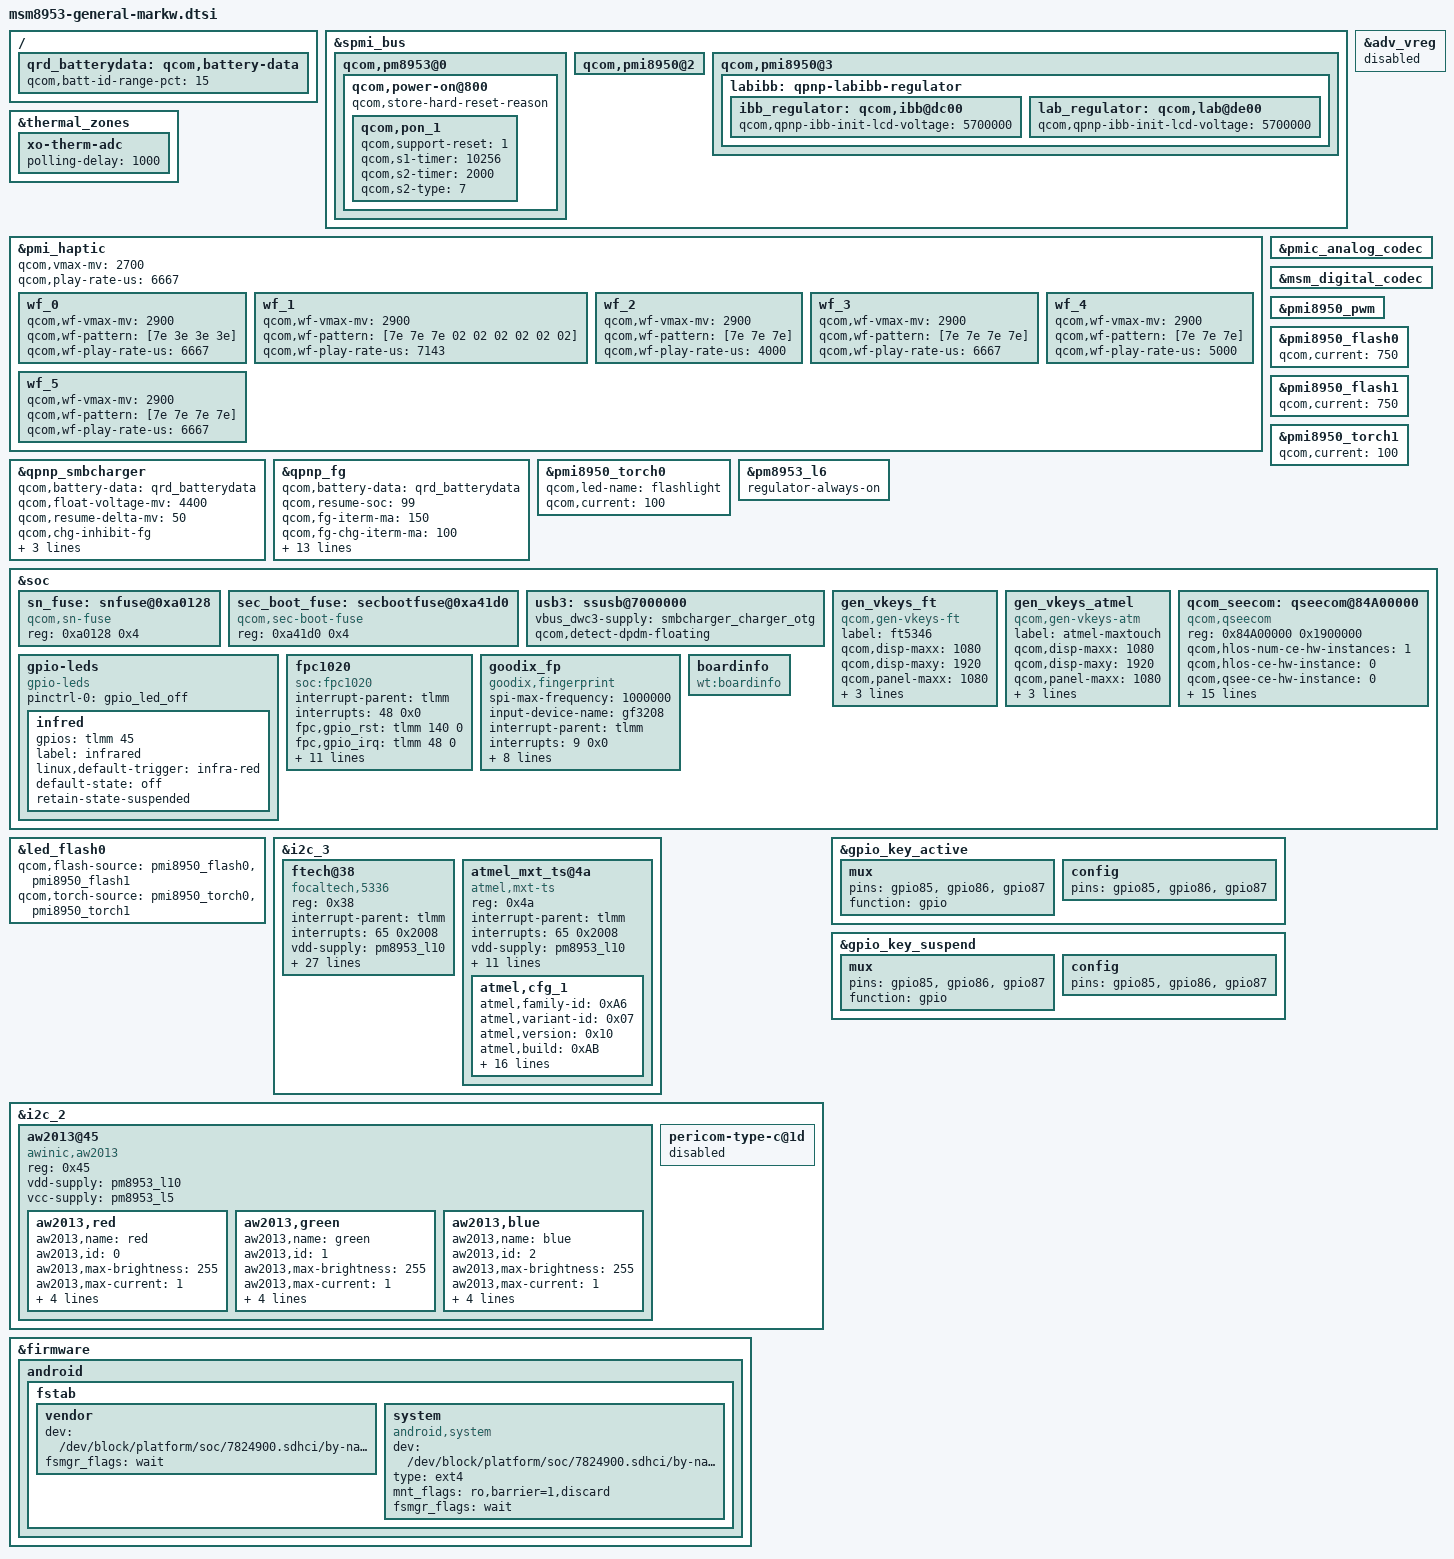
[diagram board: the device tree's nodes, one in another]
/* Copyright (c) 2017, The Linux Foundation. All rights reserved.
 *
 * This program is free software; you can redistribute it and/or modify
 * it under the terms of the GNU General Public License version 2 and
 * only version 2 as published by the Free Software Foundation.
 *
 * This program is distributed in the hope that it will be useful,
 * but WITHOUT ANY WARRANTY; without even the implied warranty of
 * MERCHANTABILITY or FITNESS FOR A PARTICULAR PURPOSE.  See the
 * GNU General Public License for more details.
 */

&spmi_bus {
	qcom,pm8953@0 {
		qcom,power-on@800 {
			qcom,store-hard-reset-reason;
			qcom,pon_1 {
				qcom,support-reset = <1>;
				qcom,s1-timer = <10256>;
				qcom,s2-timer = <2000>;
				qcom,s2-type = <7>;
		       };
		};
		/delete-node/ qcom,pm8953_typec@bf00;
          };

	qcom,pmi8950@2 {
        /delete-node/ qcom,leds@a100;
        };
    qcom,pmi8950@3 {
		labibb: qpnp-labibb-regulator {
			ibb_regulator: qcom,ibb@dc00 {
				/delete-property/
					qcom,qpnp-ibb-use-default-voltage;
				qcom,qpnp-ibb-init-lcd-voltage = <5700000>;
			};

			lab_regulator: qcom,lab@de00 {
				/delete-property/
					qcom,qpnp-ibb-use-default-voltage;
				qcom,qpnp-ibb-init-lcd-voltage = <5700000>;
			};
		};
	};
};

&adv_vreg {
	status = "disabled";
};

&thermal_zones {
	/delete-node/ pa-therm1-adc;
};

&pmi_haptic {
	status = "okay";
	qcom,vmax-mv = <2700>;
	qcom,play-rate-us = <6667>;
	wf_0 {
		qcom,wf-vmax-mv = <2900>;
		qcom,wf-pattern = [7e 3e 3e 3e];
		qcom,wf-play-rate-us = <6667>;
	};
	wf_1 {
		qcom,wf-vmax-mv = <2900>;
		qcom,wf-pattern = [7e 7e 7e 02 02 02 02 02 02];
		qcom,wf-play-rate-us = <7143>;
	};
	wf_2 {
		qcom,wf-vmax-mv = <2900>;
		qcom,wf-pattern = [7e 7e 7e];
		qcom,wf-play-rate-us = <4000>;
	};
	wf_3 {
		qcom,wf-vmax-mv = <2900>;
		qcom,wf-pattern = [7e 7e 7e 7e];
		qcom,wf-play-rate-us = <6667>;
	};
	wf_4 {
		qcom,wf-vmax-mv = <2900>;
		qcom,wf-pattern = [7e 7e 7e];
		qcom,wf-play-rate-us = <5000>;
	};
	wf_5 {
		qcom,wf-vmax-mv = <2900>;
		qcom,wf-pattern = [7e 7e 7e 7e];
		qcom,wf-play-rate-us = <6667>;
	};
};

&pmic_analog_codec {
	status = "okay";
};

&msm_digital_codec {
	status = "okay";
};

&qpnp_smbcharger {
	qcom,battery-data = <&qrd_batterydata>;
	qcom,float-voltage-mv = <4400>;
	qcom,resume-delta-mv = <50>;
        qcom,chg-inhibit-fg;
	qcom,thermal-mitigation = <2000 1200 1000 800 800>;
	qcom,charge-unknown-battery;
	/delete-property/ qcom,parallel-usb-min-current-ma;
	/delete-property/ qcom,parallel-usb-9v-min-current-ma;
	/delete-property/ qcom,parallel-allowed-lowering-ma;
	/delete-property/ qcom,chg-led-sw-controls;
	/delete-property/ qcom,chg-led-support;
	/delete-property/ qcom,external-typec;
	/delete-property/ qcom,typec-psy-name;
};

&qpnp_fg {
        qcom,battery-data = <&qrd_batterydata>;
	qcom,resume-soc = <99>;
	qcom,fg-iterm-ma = <150>;
	qcom,fg-chg-iterm-ma = <100>;
	qcom,fg-cutoff-voltage-mv = <3400>;
	qcom,fg-cc-cv-threshold-mv = <4390>;
	qcom,fg-vbat-estimate-diff-mv = <3200>;
	qcom,cold-bat-decidegc = <(0)>;
	qcom,cool-bat-decidegc = <(100)>;
	qcom,hot-bat-decidegc = <600>;
	qcom,warm-bat-decidegc = <450>;
	qcom,cl-max-increment-deciperc = <1>;
	qcom,cl-max-decrement-deciperc = <1>;
	qcom,fg-delta-soc = <1>;
        qcom,bad-battery-detection-enable;
	qcom,hold-soc-while-full;
	qcom,thermal-coefficients = [c2 86 bb 50 cf 37];
};

&pmi8950_pwm {
    status = "okay";
};
		
&pmi8950_flash0 {
	qcom,current = <750>;
};

&pmi8950_flash1 {
	qcom,current = <750>;
};

&pmi8950_torch1 {
	qcom,current = <100>;
};

&pmi8950_torch0 {
    qcom,led-name = "flashlight";
	qcom,current = <100>;
};

&pm8953_l6 {
	regulator-always-on;
};

&soc {
	sn_fuse: snfuse@0xa0128 {
		compatible = "qcom,sn-fuse";
		reg = <0xa0128 0x4>;
		reg-names = "sn-base";
	};

	sec_boot_fuse: secbootfuse@0xa41d0 {
		compatible = "qcom,sec-boot-fuse";
		reg = <0xa41d0 0x4>;
		reg-names = "sec-boot-base";
	};

	usb3: ssusb@7000000 {
		vbus_dwc3-supply = <&smbcharger_charger_otg>;
		qcom,detect-dpdm-floating;
	};

	gen_vkeys_ft {
		compatible = "qcom,gen-vkeys-ft";
		label = "ft5346";
		qcom,disp-maxx = <1080>;
		qcom,disp-maxy = <1920>;
		qcom,panel-maxx = <1080>;
		qcom,panel-maxy = <2080>;
		qcom,key-codes = <139 172 158>;
		qcom,y-offset = <0>;
	};
	gen_vkeys_atmel {
		compatible = "qcom,gen-vkeys-atm";
		label = "atmel-maxtouch";
		qcom,disp-maxx = <1080>;
		qcom,disp-maxy = <1920>;
		qcom,panel-maxx = <1080>;
		qcom,panel-maxy = <2080>;
		qcom,key-codes = <139 172 158>;
		qcom,y-offset = <0>;
	};

	qcom_seecom: qseecom@84A00000 {
		compatible = "qcom,qseecom";
		reg = <0x84A00000 0x1900000>;
		reg-names = "secapp-region";
		qcom,hlos-num-ce-hw-instances = <1>;
		qcom,hlos-ce-hw-instance = <0>;
		qcom,qsee-ce-hw-instance = <0>;
		qcom,disk-encrypt-pipe-pair = <2>;
		qcom,support-fde;
		qcom,msm-bus,name = "qseecom-noc";
		qcom,msm-bus,num-cases = <4>;
		qcom,msm-bus,num-paths = <1>;
		qcom,support-bus-scaling;
		qcom,appsbl-qseecom-support;
		qcom,msm-bus,vectors-KBps =
			<55 512 0 0>,
			<55 512 0 0>,
			<55 512 120000 1200000>,
			<55 512 393600 3936000>;
		clocks = <&clock_gcc clk_crypto_clk_src>,
			 <&clock_gcc clk_gcc_crypto_clk>,
			 <&clock_gcc clk_gcc_crypto_ahb_clk>,
			 <&clock_gcc clk_gcc_crypto_axi_clk>;
		clock-names = "core_clk_src", "core_clk",
				"iface_clk", "bus_clk";
		qcom,ce-opp-freq = <100000000>;
	};

	/delete-node/ qseecom@85b00000;

	gpio-leds {
		compatible = "gpio-leds";
		status = "okay";
		pinctrl-names = "default";
		pinctrl-0 = <&gpio_led_off>;

			infred {
			gpios = <&tlmm 45 0>;
			label = "infrared";
			linux,default-trigger = "infra-red";
			default-state = "off";
			retain-state-suspended;
		};
	};

	fpc1020 {
		compatible = "soc:fpc1020";

		interrupt-parent = <&tlmm>;
		interrupts = <48 0x0>;

		fpc,gpio_rst    = <&tlmm 140 0>;
		fpc,gpio_irq    = <&tlmm 48 0>;

		vcc_spi-supply  = <&pm8953_l5>;
		vdd_ana-supply  = <&pm8953_l5>;
		vdd_io-supply   = <&pm8953_l5>;

		fpc,enable-on-boot;
		/delete-property/
		fpc,enable-wakeup;

		fpc,spi-max-frequency = <4800000>;

		/*For SPI Clock Handled by Linux*/
		clock-names = "iface_clk", "core_clk";
		clocks = <&clock_gcc clk_gcc_blsp1_ahb_clk>,
		<&clock_gcc clk_gcc_blsp1_qup1_spi_apps_clk>;

		pinctrl-names = "fpc1020_spi_active",
			"fpc1020_reset_reset",
			"fpc1020_reset_active",
			"fpc1020_irq_active";

		pinctrl-0 = <&fpc_spi_active>;
		pinctrl-1 = <&fpc_reset_reset>;
		pinctrl-2 = <&fpc_reset_active>;
		pinctrl-3 = <&fpc_irq_active>;
	};

	goodix_fp {
		compatible = "goodix,fingerprint";
		spi-max-frequency = <1000000>;
		input-device-name = "gf3208";
		interrupt-parent = <&tlmm>;
		interrupts = <9 0x0>;

		goodix,gpio_reset    = <&tlmm 140 0>;
		goodix,gpio_irq      = <&tlmm 48 0>;

		clock-names = "iface_clk", "core_clk";
		clocks = <&clock_gcc clk_gcc_blsp1_ahb_clk>,
		<&clock_gcc clk_gcc_blsp1_qup1_spi_apps_clk>;

		pinctrl-names = "goodixfp_spi_active",
				"goodixfp_reset_reset",
				"goodixfp_reset_active",
				"goodixfp_irq_active";

		pinctrl-0 = <&goodix_spi_active>;
		pinctrl-1 = <&goodix_reset_reset>;
		pinctrl-2 = <&goodix_reset_active>;
		pinctrl-3 = <&goodix_irq_active>;
    };

	boardinfo {
		compatible = "wt:boardinfo";
	};
};

&led_flash0 {
        /delete-property/ qcom,switch-source;
	qcom,flash-source = <&pmi8950_flash0 &pmi8950_flash1>;
	qcom,torch-source = <&pmi8950_torch0 &pmi8950_torch1>;
};

&i2c_3  {
	status = "okay";
		/delete-node/ synaptics@4b;
		ftech@38 {
			compatible = "focaltech,5336";
			reg = <0x38>;
			interrupt-parent = <&tlmm>;
			interrupts = <65 0x2008>;
			vdd-supply = <&pm8953_l10>;
			vcc_i2c-supply = <&pm8953_l5>;
			/* pins used by touchscreen */
			pinctrl-names = "pmx_ts_active","pmx_ts_suspend",
				"pmx_ts_release";
			pinctrl-0 = <&ts_int_active &ts_reset_active>;
			pinctrl-1 = <&ts_int_suspend &ts_reset_suspend>;
			pinctrl-2 = <&ts_release>;
			ftech,name = "ft5336";
			ftech,family-id = <0x36>;
			ftech,reset-gpio = <&tlmm 64 0x00>;
			ftech,irq-gpio = <&tlmm 65 0x2008>;
			ftech,display-coords = <0 0 1080 1920>;
			ftech,panel-coords = <0 0 1080 1920>;
			/*ftech,button-map= <139 102 158>;*/
			ftech,virtual-key1 = <139 180 2000>;/*menu*/
			ftech,virtual-key2 = <172 540 2000>;/*home*/
			ftech,virtual-key3 = <158 900 2000>;/*back*/
			ftech,no-force-update;
			ftech,i2c-pull-up;
			ftech,group-id = <1>;
			ftech,hard-reset-delay-ms = <20>;
			ftech,soft-reset-delay-ms = <200>;
			ftech,num-max-touches = <10>;
			ftech,fw-delay-aa-ms = <30>;
			ftech,fw-delay-55-ms = <30>;
			ftech,fw-upgrade-id1 = <0x79>;
			ftech,fw-upgrade-id2 = <0x18>;
			ftech,fw-delay-readid-ms = <10>;
			ftech,fw-delay-era-flsh-ms = <2000>;
			ftech,fw-auto-cal;
			ftech,ignore-id-check;
	};
	atmel_mxt_ts@4a {
		compatible = "atmel,mxt-ts";
		reg = <0x4a>;
		interrupt-parent = <&tlmm>;
		interrupts = <65 0x2008>;
		vdd-supply = <&pm8953_l10>;
		vcc_i2c-supply = <&pm8953_l5>;
		/* pins used by touchscreen */
		pinctrl-names = "pmx_ts_active","pmx_ts_suspend","pmx_ts_release";
		pinctrl-0 = <&ts_int_active &ts_reset_active>;
		pinctrl-1 = <&ts_int_suspend &ts_reset_suspend>;
		pinctrl-2 = <&ts_release>;
		atmel,reset-gpio = <&tlmm 64 0x0>;
		atmel,irq-gpio = <&tlmm 65 0x2008>;
		atmel,mxt-fw-name = "mxt_308u.fw";
		atmel,config-array-size = <1>;
		atmel,default-config = <0>;
		atmel,irqflags = <0x2008>;
		atmel,vendor-id-byte = /bits/ 8 <0 3>;
		atmel,cfg_1 {
			atmel,family-id = <0xA6>;
			atmel,variant-id = <0x07>;
			atmel,version = <0x10>;
			atmel,build = <0xAB>;
			atmel,rev-id = <0x2>;
			atmel,panel-id = <0x31>;
			atmel,mxt-cfg-name = "mxt_308u_b5_f.raw";
			atmel,vendor-id = /bits/ 8 <0x31 0x31>; /* Biel HW ver 1 */
			atmel,key-codes = <139 172 158>;
			atmel,selfintthr-stylus = <0>;
			atmel,t71-tchthr-pos = <22>;
			atmel,self-chgtime-min = <0>;
			atmel,self-chgtime-max = <0>;
			atmel,mult-intthr-sensitive = <12>;
			atmel,mult-intthr-not-sensitive = <17>;
			atmel,atchthr-sensitive = <6>;
			atmel,mult-tchthr-sensitive = <0>;
			atmel,mult-tchthr-not-sensitive = <0>;
			atmel,wake-up-self-adcx = <16>;
			atmel,support-wakeup-gesture;
			};
	   };		
};

&i2c_2  { /* i2c 6 */
		aw2013@45 {
			compatible = "awinic,aw2013";
			reg = <0x45>;
			vdd-supply = <&pm8953_l10>;
			vcc-supply = <&pm8953_l5>;

			aw2013,red {
				aw2013,name = "red";
				aw2013,id = <0>;
				aw2013,max-brightness = <255>;
				aw2013,max-current = <1>;
				aw2013,rise-time-ms = <3>;
				aw2013,hold-time-ms = <1>;
				aw2013,fall-time-ms = <3>;
				aw2013,off-time-ms = <3>;
			};

			aw2013,green {
				aw2013,name = "green";
				aw2013,id = <1>;
				aw2013,max-brightness = <255>;
				aw2013,max-current = <1>;
				aw2013,rise-time-ms = <3>;
				aw2013,hold-time-ms = <1>;
				aw2013,fall-time-ms = <3>;
				aw2013,off-time-ms = <3>;
			};

			aw2013,blue {
				aw2013,name = "blue";
				aw2013,id = <2>;
				aw2013,max-brightness = <255>;
				aw2013,max-current = <1>;
				aw2013,rise-time-ms = <3>;
				aw2013,hold-time-ms = <1>;
				aw2013,fall-time-ms = <3>;
				aw2013,off-time-ms = <3>;
			};
		};
	pericom-type-c@1d {
		status="disabled";
	};
};

&thermal_zones {
	xo-therm-adc {
		polling-delay = <1000>;
	};
};

/ {
	/delete-node/ qcom,battery-data;
	qrd_batterydata: qcom,battery-data {
		qcom,batt-id-range-pct = <15>;
		
		#include "battery/MARKW-qrd-Coslight-4v4-4000mah.dtsi"
		#include "battery/MARKW-qrd-Feimaotui-4v4-4000mah.dtsi"
		#include "battery/MARKW-qrd-Default-4v4-4000mah.dtsi"
	};
};

&firmware {
	android {
		/delete-node/ vbmeta;

		fstab {
			vendor {
				dev = "/dev/block/platform/soc/7824900.sdhci/by-name/cust";
				fsmgr_flags = "wait";
				status = "ok";
			};

			system {
				compatible = "android,system";
				dev = "/dev/block/platform/soc/7824900.sdhci/by-name/system";
				type = "ext4";
				mnt_flags = "ro,barrier=1,discard";
				fsmgr_flags = "wait";
				status = "ok";
			};
		};
	};
};

&gpio_key_active {
	mux {
		pins = "gpio85", "gpio86", "gpio87";
		function = "gpio";
	};

	config {
		pins = "gpio85", "gpio86", "gpio87";
	};
};

&gpio_key_suspend {
	mux {
		pins = "gpio85", "gpio86", "gpio87";
		function = "gpio";
	};

	config {
		pins = "gpio85", "gpio86", "gpio87";
	};
};
